# HK32F0301M register map
Vendor: HKMicroChip Ltd.; Series: HK32F0301M; File version: 1.0
CPU: CM0 r0p0, little endian, no MPU, no FPU, 3 interrupt priority bits
Registers are 32-bit, read-write, reset 0x0 unless marked. A register's access mark holds for its fields unless they carry their own. Offsets are from the block's base; [hi:lo] are bit positions; {n}, {i} and the like mark numbered series.

## WWDG — Window watchdog
Base 0x40002C00
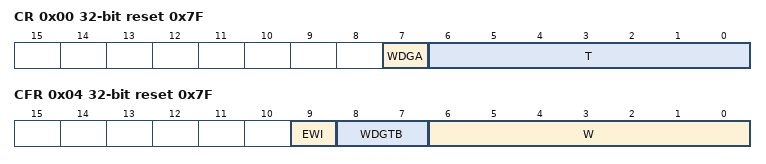
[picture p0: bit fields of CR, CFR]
0x00 CR reset 0x7F — Control register
  [7] WDGA — Activation bit
  [6:0] T — 7-bit counter
0x04 CFR reset 0x7F — Configuration register
  [9] EWI — Early wakeup interrupt
  [8:7] WDGTB — Timer base
  [6:0] W — 7-bit window value
0x08 SR — Status register
  [0] EWIF — Early wakeup interrupt flag

## TIM6 — Basic-timers
Base 0x40001000
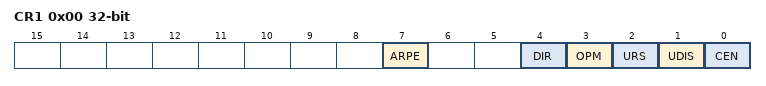
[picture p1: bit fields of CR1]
0x00 CR1 — control register 1
  [7] ARPE — Auto-reload preload enable
  [4] DIR — Direction
  [3] OPM — One-pulse mode
  [2] URS — Update request source
  [1] UDIS — Update disable
  [0] CEN — Counter enable
0x04 CR2 — control register 2
  [6:4] MMS — Master mode selection
0x0C DIER — Interrupt enable register
  [0] UIE — Update interrupt enable
0x10 SR — status register
  [0] UIF — Update interrupt flag
0x14 EGR wo — event generation register
  [0] UG — Update generation
0x24 CNT — counter
  [15:0] CNT — Low counter value
0x28 PSC — prescaler
  [15:0] PSC — Prescaler value
0x2C ARR — auto-reload register
  [15:0] ARR — Low Auto-reload value

## EXTI — External interrupt/event controller
Base 0x40010400
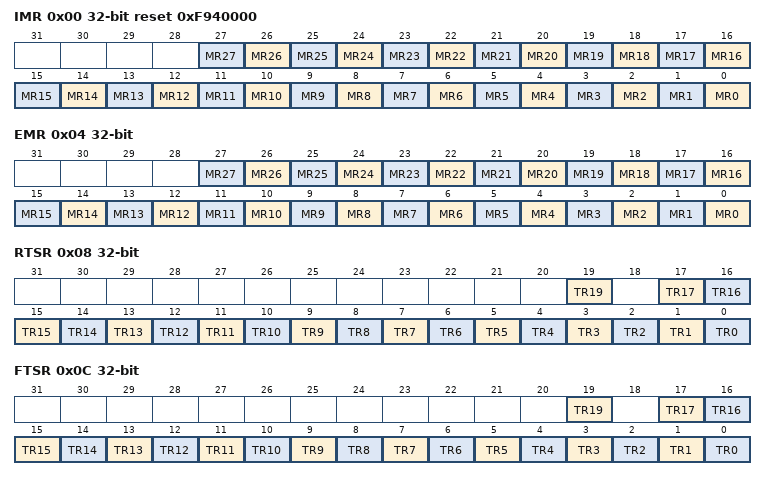
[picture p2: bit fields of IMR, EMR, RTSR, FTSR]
0x00 IMR reset 0xF940000 — Interrupt mask register (EXTI_IMR)
  [n] MR{n} (n=0..27) — Interrupt Mask on line {n}
0x04 EMR — Event mask register (EXTI_EMR)
  [n] MR{n} (n=0..27) — Event Mask on line {n}
0x08 RTSR — Rising Trigger selection register (EXTI_RTSR)
  [19] TR19 — Rising trigger event configuration of line 19
  [n] TR{n} (n=0..17) — Rising trigger event configuration of line {n}
0x0C FTSR — Falling Trigger selection register (EXTI_FTSR)
  [19] TR19 — Falling trigger event configuration of line 19
  [n] TR{n} (n=0..17) — Falling trigger event configuration of line {n}
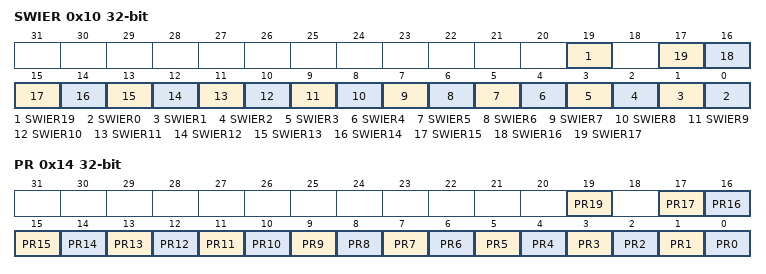
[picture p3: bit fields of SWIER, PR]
0x10 SWIER — Software interrupt event register (EXTI_SWIER)
  [19] SWIER19 — Software Interrupt on line 19
  [n] SWIER{n} (n=0..17) — Software Interrupt on line {n}
0x14 PR — Pending register (EXTI_PR)
  [19] PR19 — Pending bit 19
  [n] PR{n} (n=0..17) — Pending bit {n}

## NVIC — Nested Vectored Interrupt Controller
Base 0xE000E100
0x00 ISER — Interrupt Set Enable Register
  [31:0] SETENA
0x80 ICER — Interrupt Clear Enable Register
  [31:0] CLRENA
0x100 ISPR — Interrupt Set-Pending Register
  [31:0] SETPEND
0x180 ICPR — Interrupt Clear-Pending Register
  [31:0] CLRPEND
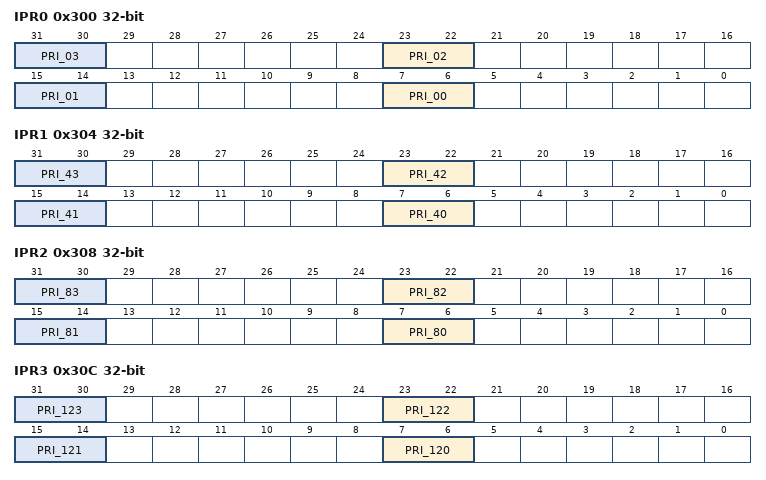
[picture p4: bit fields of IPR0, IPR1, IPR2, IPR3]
0x300 IPR0 — Interrupt Priority Register 0
  [8n+7:8n+6] PRI_{n:02} (n=0..3)
0x304 IPR1 — Interrupt Priority Register 1
  [8n-313:8n-314] PRI_{n} (n=40..43)
0x308 IPR2 — Interrupt Priority Register 2
  [8n-633:8n-634] PRI_{n} (n=80..83)
0x30C IPR3 — Interrupt Priority Register 3
  [8n-953:8n-954] PRI_{n} (n=120..123)
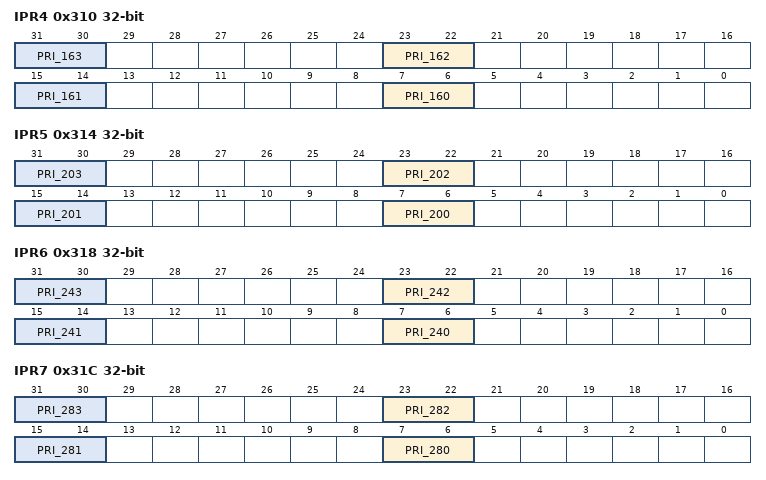
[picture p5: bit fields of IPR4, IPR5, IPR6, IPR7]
0x310 IPR4 — Interrupt Priority Register 4
  [8n-1273:8n-1274] PRI_{n} (n=160..163)
0x314 IPR5 — Interrupt Priority Register 5
  [8n-1593:8n-1594] PRI_{n} (n=200..203)
0x318 IPR6 — Interrupt Priority Register 6
  [8n-1913:8n-1914] PRI_{n} (n=240..243)
0x31C IPR7 — Interrupt Priority Register 7
  [8n-2233:8n-2234] PRI_{n} (n=280..283)

## SYSCFG — System configuration controller
Base 0x40010000
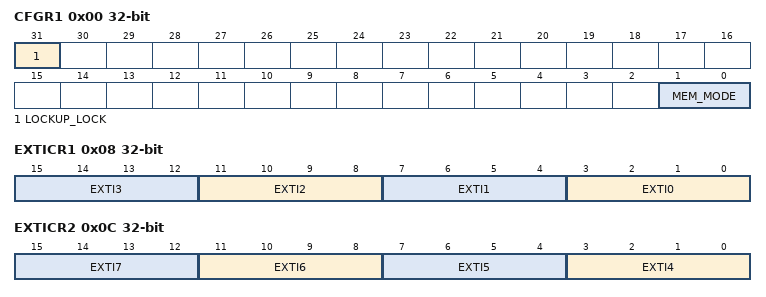
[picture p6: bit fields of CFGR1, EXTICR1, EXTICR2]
0x00 CFGR1 — configuration register 1
  [31] LOCKUP_LOCK
  [1:0] MEM_MODE — Memory mapping selection bits
0x08 EXTICR1 — external interrupt configuration register 1
  [4n+3:4n] EXTI{n} (n=0..3) — EXTI {n} configuration bits
0x0C EXTICR2 — external interrupt configuration register 2
  [4n-13:4n-16] EXTI{n} (n=4..7) — EXTI {n} configuration bits

## ADC — Analog-to-digital converter
Base 0x40012400
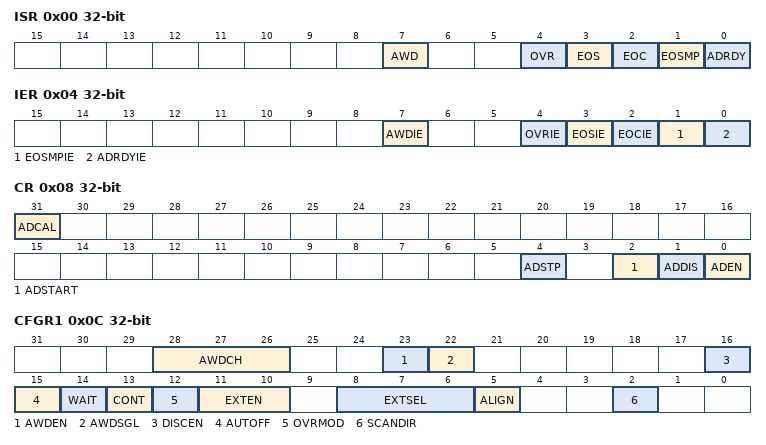
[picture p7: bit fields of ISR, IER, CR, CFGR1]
0x00 ISR — interrupt and status register
  [7] AWD — Analog watchdog flag
  [4] OVR — ADC overrun
  [3] EOS — End of sequence flag
  [2] EOC — End of conversion flag
  [1] EOSMP — End of sampling flag
  [0] ADRDY — ADC ready
0x04 IER — interrupt enable register
  [7] AWDIE — Analog watchdog interrupt enable
  [4] OVRIE — Overrun interrupt enable
  [3] EOSIE — End of conversion sequence interrupt enable
  [2] EOCIE — End of conversion interrupt enable
  [1] EOSMPIE — End of sampling flag interrupt enable
  [0] ADRDYIE — ADC ready interrupt enable
0x08 CR — control register
  [31] ADCAL — ADC calibration
  [4] ADSTP — ADC stop conversion command
  [2] ADSTART — ADC start conversion command
  [1] ADDIS — ADC disable command
  [0] ADEN — ADC enable command
0x0C CFGR1 — configuration register 1
  [28:26] AWDCH — Analog watchdog channel selection
  [23] AWDEN — Analog watchdog enable
  [22] AWDSGL — Enable the watchdog on a single channel or on all channels
  [16] DISCEN — Discontinuous mode
  [15] AUTOFF — Auto-off mode
  [14] WAIT — Wait conversion mode
  [13] CONT — Single / continuous conversion mode
  [12] OVRMOD — Overrun management mode
  [11:10] EXTEN — External trigger enable and polarity selection
  [8:6] EXTSEL — External trigger selection
  [5] ALIGN — Data alignment
  [2] SCANDIR — Scan sequence direction
0x10 CFGR2 reset 0x8000 — configuration register 2
  [31:30] CKMODE
0x14 SMPR — sampling time register
  [2:0] SMP — Sampling time selection
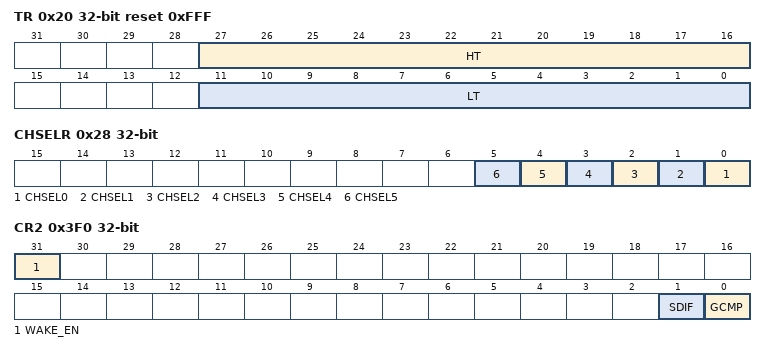
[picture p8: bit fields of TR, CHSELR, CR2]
0x20 TR reset 0xFFF — watchdog threshold register
  [27:16] HT — Analog watchdog higher threshold
  [11:0] LT — Analog watchdog lower threshold
0x28 CHSELR — channel selection register
  [n] CHSEL{n} (n=0..5) — Channel-x selection
0x40 DR ro — data register
  [15:0] DATA — Converted data
0x308 CCR — common configuration register
  [22] VREFEN — Temperature sensor and VREFINT enable
0x3F0 CR2 — ADC config register 2
  [31] WAKE_EN, [1] SDIF, [0] GCMP

## Flash
Base 0x40022000
0x00 ACR reset 0x30 — Flash access control register
  [2:0] LATENCY
0x04 KEYR wo — Flash key register
  [31:0] FKEYR — Flash Key
0x08 OPTKEYR wo — Flash option key register
  [31:0] OPTKEYR — Option byte key
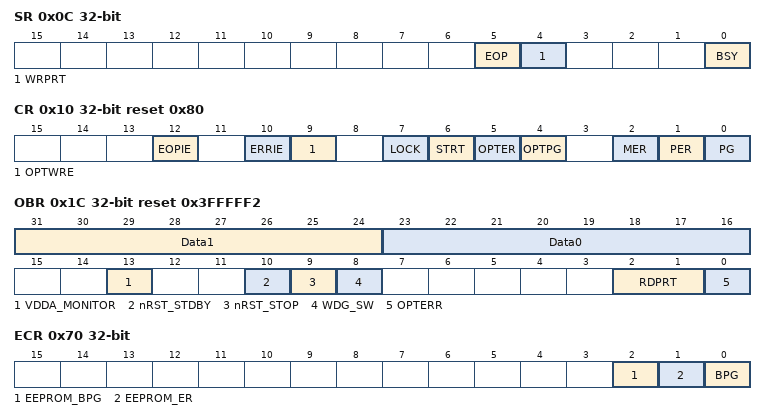
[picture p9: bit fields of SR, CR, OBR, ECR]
0x0C SR access per field — Flash status register
  [5] EOP rw — End of operation
  [4] WRPRT rw — Write protection error
  [0] BSY ro — Busy
0x10 CR reset 0x80 — Flash control register
  [12] EOPIE — End of operation interrupt enable
  [10] ERRIE — Error interrupt enable
  [9] OPTWRE — Option bytes write enable
  [7] LOCK
  [6] STRT — Start
  [5] OPTER — Option byte erase
  [4] OPTPG — Option byte program
  [2] MER — Main Flash Mass erase
  [1] PER — Main Flash Page erase
  [0] PG — Main Flash Halfword Program
0x14 AR wo — Flash address register
  [31:0] FAR — Flash address
0x1C OBR ro reset 0x3FFFFF2 — Option byte register
  [31:24] Data1
  [23:16] Data0
  [13] VDDA_MONITOR
  [10] nRST_STDBY
  [9] nRST_STOP
  [8] WDG_SW
  [2:1] RDPRT — Read protection level status
  [0] OPTERR — Option byte error
0x20 WRPR ro reset 0xFFFFFFFF — Write protection register
  [31:0] WRP — Write protect
0x70 ECR — Flash ecr register
  [2] EEPROM_BPG — EEPROM Program by Byte
  [1] EEPROM_ER — EEPROM Erase by Byte
  [0] BPG — Main flash Program by Byte
0x74 INT_VEC_OFFSET — Interruput Vector table address offset register
  [13:0] INT_VEC_OFFSET — Interruput Vector table address offset

## DBGMCU — Debug support
Base 0x40015800
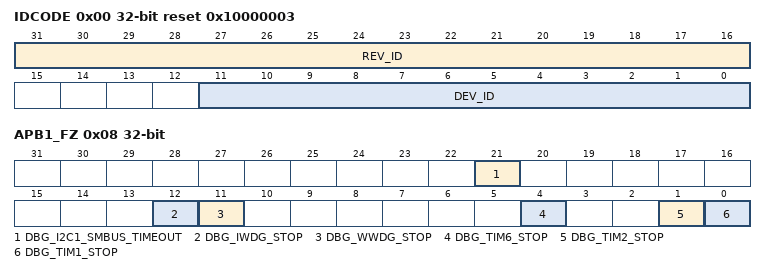
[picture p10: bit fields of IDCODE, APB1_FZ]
0x00 IDCODE ro reset 0x10000003 — MCU Device ID Code Register
  [31:16] REV_ID — Revision Identifier
  [11:0] DEV_ID — Device Identifier
0x04 CR — MCU Device debug control Register
  [1] DBG_STOP — Debug Stop Mode
0x08 APB1_FZ access per field — MCU Device debug apb1 Register
  [21] DBG_I2C1_SMBUS_TIMEOUT rw — Debug I2C1_SMBUS Stop Mode.
  [12] DBG_IWDG_STOP ro — Debug IWDG Stop Mode
  [11] DBG_WWDG_STOP ro — Debug WWDG Stop Mode
  [4] DBG_TIM6_STOP rw — Debug TIM6 Stop Mode
  [1] DBG_TIM2_STOP rw — Debug TIM2 Stop Mode
  [0] DBG_TIM1_STOP rw — Debug TIM1 Stop Mode

## AWU — AWU module
Base 0x40007800
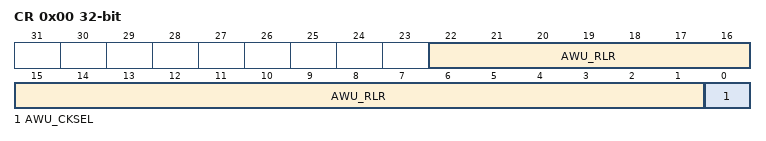
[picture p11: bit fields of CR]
0x00 CR — AWU control Register
  [22:1] AWU_RLR, [0] AWU_CKSEL
0x04 SR ro — AWU status Register
  [0] AWU_BUSY

## Beeper — Beeper module
Base 0x40007C00
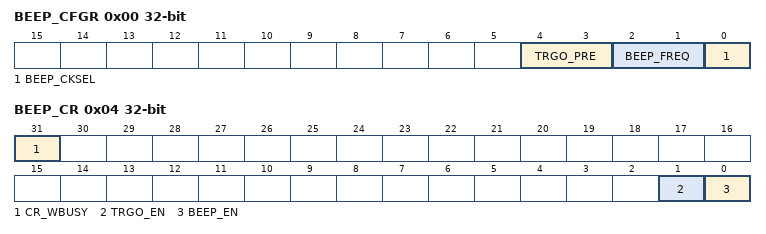
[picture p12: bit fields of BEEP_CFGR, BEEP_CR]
0x00 BEEP_CFGR
  [4:3] TRGO_PRE, [2:1] BEEP_FREQ, [0] BEEP_CKSEL
0x04 BEEP_CR
  [31] CR_WBUSY, [1] TRGO_EN, [0] BEEP_EN
